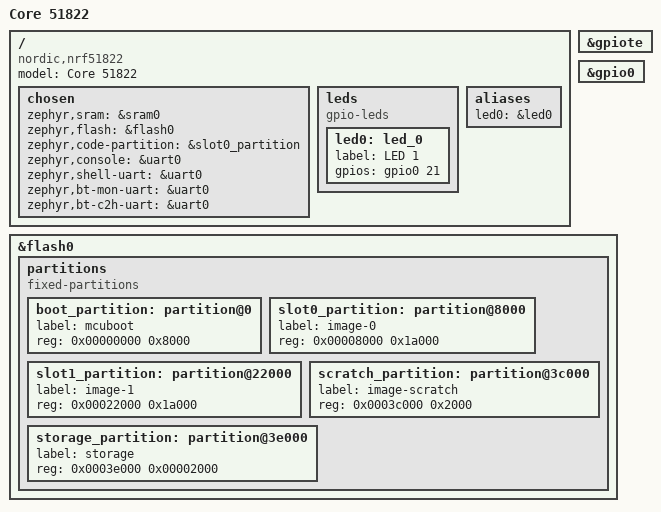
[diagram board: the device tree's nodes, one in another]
/*
 * Copyright (c) 2017 Linaro Limited
 *
 * SPDX-License-Identifier: Apache-2.0
 */

/dts-v1/;
#include <nordic/nrf51822_qfaa.dtsi>
//#include "core51_nrf51822-pinctrl.dtsi"
#include <zephyr/dt-bindings/input/input-event-codes.h>

/ {
	model = "Core 51822";
	compatible = "nordic,nrf51822";

	chosen {
		zephyr,sram = &sram0;
		zephyr,flash = &flash0;
		zephyr,code-partition = &slot0_partition;
		zephyr,console = &uart0;
		zephyr,shell-uart = &uart0;
		zephyr,bt-mon-uart = &uart0;
		zephyr,bt-c2h-uart = &uart0;
	};

	leds {
		compatible = "gpio-leds";
		led0: led_0 {
			label = "LED 1";
			gpios = <&gpio0 21 0>;
		};
	};

	/* These aliases are provided for compatibility with samples */
	aliases {
		led0 = &led0;
	};
};

&gpiote {
	status = "okay";
};

&gpio0 {
	status = "okay";
};

&flash0 {
	partitions {
		compatible = "fixed-partitions";
		#address-cells = <1>;
		#size-cells = <1>;

		boot_partition: partition@0 {
			label = "mcuboot";
			reg = <0x00000000 0x8000>;
		};
		slot0_partition: partition@8000 {
			label = "image-0";
			reg = <0x00008000 0x1a000>;
		};
		slot1_partition: partition@22000 {
			label = "image-1";
			reg = <0x00022000 0x1a000>;
		};
		scratch_partition: partition@3c000 {
			label = "image-scratch";
			reg = <0x0003c000 0x2000>;
		};
		storage_partition: partition@3e000 {
			label = "storage";
			reg = <0x0003e000 0x00002000>;
		};
	};
};
